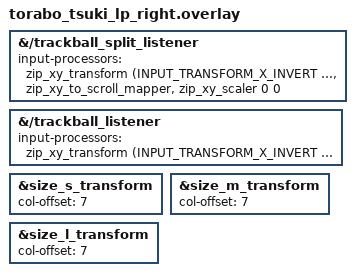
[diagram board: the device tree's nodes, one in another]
#include "torabo_tsuki_lp.dtsi"
#include <input/processors.dtsi>
#include <dt-bindings/zmk/input_transform.h>

/* スニペットが生成するリスナーを探して、中身を上書きする */
&{/trackball_split_listener} {
    input-processors = 
        <&zip_xy_transform (INPUT_TRANSFORM_X_INVERT | INPUT_TRANSFORM_Y_INVERT)>,
        <&zip_xy_to_scroll_mapper>,
        <&zip_xy_scaler 0 0>;
};

/* 右手用（通常のマウス） */
&{/trackball_listener} {
    input-processors = <&zip_xy_transform (INPUT_TRANSFORM_X_INVERT | INPUT_TRANSFORM_Y_INVERT)>;
};

&size_s_transform {
    col-offset = <7>;
};

&size_m_transform {
    col-offset = <7>;
};

&size_l_transform {
    col-offset = <7>;
};
